VERSION "created by canmatrix"

NS_ :

BS_:

BU_: User ADM_PC_LL25 ADM_PC_BC25 ADM_PC_BP25 ADM_PC_BI25

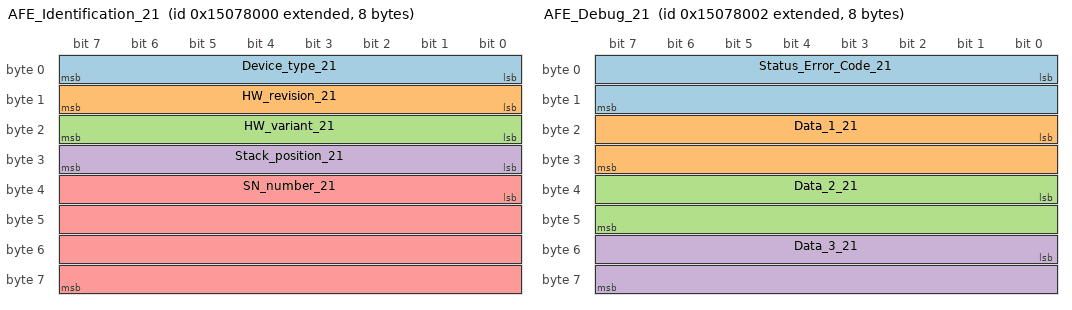
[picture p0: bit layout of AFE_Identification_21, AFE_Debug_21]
BO_ 2500296704 AFE_Identification_21: 8 ADM_PC_BP25
 SG_ Device_type_21 : 0|8@1+ (1,0) [0|255] "" Vector__XXX
 SG_ HW_revision_21 : 8|8@1+ (1,0) [0|255] "" Vector__XXX
 SG_ HW_variant_21 : 16|8@1+ (1,0) [0|255] "" Vector__XXX
 SG_ Stack_position_21 : 24|8@1+ (1,0) [0|255] "" Vector__XXX
 SG_ SN_number_21 : 32|32@1+ (1,0) [0|4294967295] "" Vector__XXX

BO_ 2500296705 AFE_FwInfo_21: 8 ADM_PC_BP25
 SG_ FW_info_mux_21 M : 56|8@1+ (1,0) [0|255] "" Vector__XXX
 SG_ FW_revision_0_21 m0 : 0|8@1+ (1,0) [0|255] "" Vector__XXX
 SG_ FW_revision_1_21 m0 : 8|8@1+ (1,0) [0|255] "" Vector__XXX
 SG_ FW_revision_2_21 m0 : 16|8@1+ (1,0) [0|255] "" Vector__XXX
 SG_ FW_revision_3_21 m0 : 24|8@1+ (1,0) [0|255] "" Vector__XXX
 SG_ FW_revision_4_21 m0 : 32|8@1+ (1,0) [0|255] "" Vector__XXX
 SG_ FW_revision_5_21 m0 : 40|8@1+ (1,0) [0|255] "" Vector__XXX
 SG_ FW_revision_6_21 m0 : 48|8@1+ (1,0) [0|255] "" Vector__XXX
 SG_ FW_revision_7_21 m1 : 0|8@1+ (1,0) [0|255] "" Vector__XXX
 SG_ FW_revision_8_21 m1 : 8|8@1+ (1,0) [0|255] "" Vector__XXX
 SG_ FW_revision_9_21 m1 : 16|8@1+ (1,0) [0|255] "" Vector__XXX
 SG_ FW_revision_10_21 m1 : 24|8@1+ (1,0) [0|255] "" Vector__XXX
 SG_ FW_revision_11_21 m1 : 32|8@1+ (1,0) [0|255] "" Vector__XXX
 SG_ FW_revision_12_21 m1 : 40|8@1+ (1,0) [0|255] "" Vector__XXX
 SG_ FW_revision_13_21 m1 : 48|8@1+ (1,0) [0|255] "" Vector__XXX
 SG_ FW_datecode_0_21 m2 : 0|8@1+ (1,0) [0|255] "" Vector__XXX
 SG_ FW_datecode_1_21 m2 : 8|8@1+ (1,0) [0|255] "" Vector__XXX
 SG_ FW_datecode_2_21 m2 : 16|8@1+ (1,0) [0|255] "" Vector__XXX
 SG_ FW_datecode_3_21 m2 : 24|8@1+ (1,0) [0|255] "" Vector__XXX
 SG_ FW_datecode_4_21 m2 : 32|8@1+ (1,0) [0|255] "" Vector__XXX
 SG_ FW_datecode_5_21 m2 : 40|8@1+ (1,0) [0|255] "" Vector__XXX
 SG_ FW_datecode_6_21 m2 : 48|8@1+ (1,0) [0|255] "" Vector__XXX
 SG_ FW_datecode_7_21 m3 : 0|8@1+ (1,0) [0|255] "" Vector__XXX
 SG_ FW_datecode_8_21 m3 : 8|8@1+ (1,0) [0|255] "" Vector__XXX
 SG_ FW_datecode_9_21 m3 : 16|8@1+ (1,0) [0|255] "" Vector__XXX
 SG_ FW_datecode_10_21 m3 : 24|8@1+ (1,0) [0|255] "" Vector__XXX
 SG_ FW_datecode_11_21 m3 : 32|8@1+ (1,0) [0|255] "" Vector__XXX
 SG_ FW_datecode_12_21 m3 : 40|8@1+ (1,0) [0|255] "" Vector__XXX
 SG_ FW_datecode_13_21 m3 : 48|8@1+ (1,0) [0|255] "" Vector__XXX

BO_ 2500296717 _AFE_Boot_FwInfo_21: 8 ADM_PC_BP25
 SG_ Boot_FW_info_mux_21 M : 56|8@1+ (1,0) [0|255] "" Vector__XXX
 SG_ FW_revision_0_21 m0 : 0|8@1+ (1,0) [0|255] "" Vector__XXX
 SG_ FW_revision_1_21 m0 : 8|8@1+ (1,0) [0|255] "" Vector__XXX
 SG_ FW_revision_2_21 m0 : 16|8@1+ (1,0) [0|255] "" Vector__XXX
 SG_ FW_revision_3_21 m0 : 24|8@1+ (1,0) [0|255] "" Vector__XXX
 SG_ FW_revision_4_21 m0 : 32|8@1+ (1,0) [0|255] "" Vector__XXX
 SG_ FW_revision_5_21 m0 : 40|8@1+ (1,0) [0|255] "" Vector__XXX
 SG_ FW_revision_6_21 m0 : 48|8@1+ (1,0) [0|255] "" Vector__XXX
 SG_ FW_revision_7_21 m1 : 0|8@1+ (1,0) [0|255] "" Vector__XXX
 SG_ FW_revision_8_21 m1 : 8|8@1+ (1,0) [0|255] "" Vector__XXX
 SG_ FW_revision_9_21 m1 : 16|8@1+ (1,0) [0|255] "" Vector__XXX
 SG_ FW_revision_10_21 m1 : 24|8@1+ (1,0) [0|255] "" Vector__XXX
 SG_ FW_revision_11_21 m1 : 32|8@1+ (1,0) [0|255] "" Vector__XXX
 SG_ FW_revision_12_21 m1 : 40|8@1+ (1,0) [0|255] "" Vector__XXX
 SG_ FW_revision_13_21 m1 : 48|8@1+ (1,0) [0|255] "" Vector__XXX
 SG_ FW_datecode_0_21 m2 : 0|8@1+ (1,0) [0|255] "" Vector__XXX
 SG_ FW_datecode_1_21 m2 : 8|8@1+ (1,0) [0|255] "" Vector__XXX
 SG_ FW_datecode_2_21 m2 : 16|8@1+ (1,0) [0|255] "" Vector__XXX
 SG_ FW_datecode_3_21 m2 : 24|8@1+ (1,0) [0|255] "" Vector__XXX
 SG_ FW_datecode_4_21 m2 : 32|8@1+ (1,0) [0|255] "" Vector__XXX
 SG_ FW_datecode_5_21 m2 : 40|8@1+ (1,0) [0|255] "" Vector__XXX
 SG_ FW_datecode_6_21 m2 : 48|8@1+ (1,0) [0|255] "" Vector__XXX
 SG_ FW_datecode_7_21 m3 : 0|8@1+ (1,0) [0|255] "" Vector__XXX
 SG_ FW_datecode_8_21 m3 : 8|8@1+ (1,0) [0|255] "" Vector__XXX
 SG_ FW_datecode_9_21 m3 : 16|8@1+ (1,0) [0|255] "" Vector__XXX
 SG_ FW_datecode_10_21 m3 : 24|8@1+ (1,0) [0|255] "" Vector__XXX
 SG_ FW_datecode_11_21 m3 : 32|8@1+ (1,0) [0|255] "" Vector__XXX
 SG_ FW_datecode_12_21 m3 : 40|8@1+ (1,0) [0|255] "" Vector__XXX
 SG_ FW_datecode_13_21 m3 : 48|8@1+ (1,0) [0|255] "" Vector__XXX

BO_ 2500296706 AFE_Debug_21: 8 ADM_PC_BP25
 SG_ Status_Error_Code_21 : 0|16@1+ (1,0) [0|65535] "" Vector__XXX
 SG_ Data_1_21 : 16|16@1+ (1,0) [0|65535] "" Vector__XXX
 SG_ Data_2_21 : 32|16@1+ (1,0) [0|65535] "" Vector__XXX
 SG_ Data_3_21 : 48|16@1+ (1,0) [0|65535] "" Vector__XXX

BO_ 2500296711 AFE_Status_21: 8 ADM_PC_BP25
 SG_ Running_21 : 0|1@1+ (1,0) [0|1] "" Vector__XXX
 SG_ PWM_21 : 1|1@1+ (1,0) [0|1] "" Vector__XXX
 SG_ Current_dc_loop_mode_21 : 2|1@1+ (1,0) [0|1] "" Vector__XXX
 SG_ Current_ac_loop_mode_21 : 3|1@1+ (1,0) [0|1] "" Vector__XXX
 SG_ Buck_21 : 5|1@1+ (1,0) [0|1] "" Vector__XXX
 SG_ Boost_21 : 6|1@1+ (1,0) [0|1] "" Vector__XXX
 SG_ Precharge_dc_buck_mode_21 : 7|1@1+ (1,0) [0|1] "" Vector__XXX
 SG_ Precharge_dc_boost_mode_21 : 8|1@1+ (1,0) [0|1] "" Vector__XXX
 SG_ Rectifier_3ph_21 : 9|1@1+ (1,0) [0|1] "" Vector__XXX
 SG_ Stack_mode_21 : 10|1@1+ (1,0) [0|1] "" Vector__XXX
 SG_ Master_21 : 11|1@1+ (1,0) [0|1] "" Vector__XXX
 SG_ Slave_21 : 12|1@1+ (1,0) [0|1] "" Vector__XXX
 SG_ Inverter_1ph_21 : 13|1@1+ (1,0) [0|1] "" Vector__XXX
 SG_ Boost_Neutral_21 : 14|1@1+ (1,0) [0|1] "" Vector__XXX
 SG_ Rectifier_1ph_21 : 15|1@1+ (1,0) [0|1] "" Vector__XXX
 SG_ Inverter_3ph_21 : 16|1@1+ (1,0) [0|1] "" Vector__XXX
 SG_ Ready_21 : 17|1@1+ (1,0) [0|1] "" Vector__XXX
 SG_ Inverter_1ph_Sync_21 : 18|1@1+ (1,0) [0|1] "" Vector__XXX
 SG_ Neutral_21 : 19|1@1+ (1,0) [0|1] "" Vector__XXX
 SG_ Rectifier_1ph_Buck_21 : 20|1@1+ (1,0) [0|1] "" Vector__XXX
 SG_ Inverter_1ph_Boost_21 : 21|1@1+ (1,0) [0|1] "" Vector__XXX
 SG_ Rectifier_distributed_21 : 22|1@1+ (1,0) [0|1] "" Vector__XXX
 SG_ MPPT_buck_21 : 23|1@1+ (1,0) [0|1] "" Vector__XXX
 SG_ MPPT_boost_21 : 24|1@1+ (1,0) [0|1] "" Vector__XXX
 SG_ Buck_2p_float_21 : 25|1@1+ (1,0) [0|1] "" Vector__XXX
 SG_ Inverter_1ph_Distributed_21 : 26|1@1+ (1,0) [0|1] "" Vector__XXX

BO_ 2500296710 AFE_Faults_21: 3 ADM_PC_BP25
 SG_ Protection_trip_internal_21 : 0|1@1+ (1,0) [0|1] "" Vector__XXX
 SG_ Protection_trip_external_21 : 1|1@1+ (1,0) [0|1] "" Vector__XXX
 SG_ Phase_U_overcurrent_21 : 2|1@1+ (1,0) [0|1] "" Vector__XXX
 SG_ Phase_U_overvoltage_21 : 3|1@1+ (1,0) [0|1] "" Vector__XXX
 SG_ Phase_U_undervoltage_21 : 4|1@1+ (1,0) [0|1] "" Vector__XXX
 SG_ Phase_V_overvoltage_21 : 5|1@1+ (1,0) [0|1] "" Vector__XXX
 SG_ Phase_V_undervoltage_21 : 6|1@1+ (1,0) [0|1] "" Vector__XXX
 SG_ Phase_V_overcurrent_21 : 7|1@1+ (1,0) [0|1] "" Vector__XXX
 SG_ Phase_W_overvoltage_21 : 8|1@1+ (1,0) [0|1] "" Vector__XXX
 SG_ Phase_W_undervoltage_21 : 9|1@1+ (1,0) [0|1] "" Vector__XXX
 SG_ Phase_W_overcurrent_21 : 10|1@1+ (1,0) [0|1] "" Vector__XXX
 SG_ DC_undervoltage_21 : 11|1@1+ (1,0) [0|1] "" Vector__XXX
 SG_ DC_overvoltage_21 : 12|1@1+ (1,0) [0|1] "" Vector__XXX
 SG_ MOSFET_overtemperature_21 : 13|1@1+ (1,0) [0|1] "" Vector__XXX
 SG_ Inductor_overtemperature_21 : 14|1@1+ (1,0) [0|1] "" Vector__XXX
 SG_ Keep_Alive_not_served_21 : 15|1@1+ (1,0) [0|1] "" Vector__XXX
 SG_ PLL_not_locked_21 : 16|1@1+ (1,0) [0|1] "" Vector__XXX
 SG_ NFO_21 : 20|1@1+ (1,0) [0|1] "" Vector__XXX
 SG_ Measurement_system_failure_21 : 21|1@1+ (1,0) [0|1] "" Vector__XXX
 SG_ EEPROM_failure_21 : 22|1@1+ (1,0) [0|1] "" Vector__XXX
 SG_ System_21 : 23|1@1+ (1,0) [0|1] "" Vector__XXX

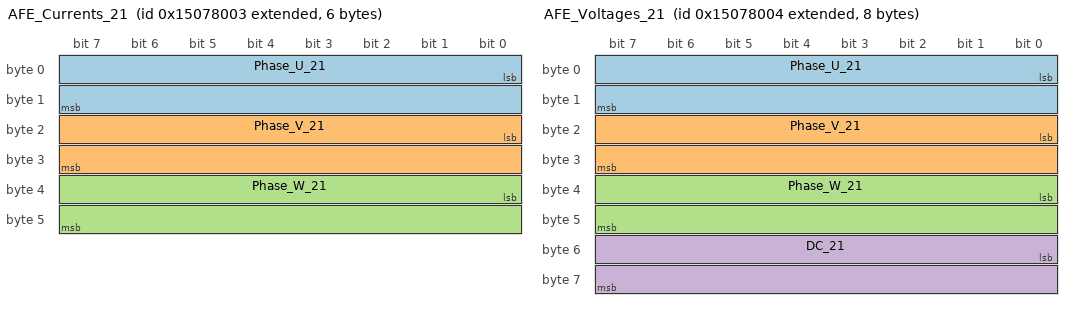
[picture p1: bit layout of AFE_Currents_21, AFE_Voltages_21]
BO_ 2500296707 AFE_Currents_21: 6 ADM_PC_BP25
 SG_ Phase_U_21 : 0|16@1- (0.01,0) [-327.68|327.67] "A" Vector__XXX
 SG_ Phase_V_21 : 16|16@1- (0.01,0) [-327.68|327.67] "A" Vector__XXX
 SG_ Phase_W_21 : 32|16@1- (0.01,0) [-327.68|327.67] "A" Vector__XXX

BO_ 2500296720 AFE_DC_Bus_current_21: 2 ADM_PC_BP25
 SG_ Bus_current_21 : 0|16@1- (0.01,0) [-327.68|327.67] "A" Vector__XXX

BO_ 2500296718 _AFE_Broadcast_21: 8 ADM_PC_BP25
 SG_ Diagnostics_Index_21 M : 56|8@1+ (1,0) [0|255] "" Vector__XXX
 SG_ Phase_U_21 m1 : 8|16@1- (0.01,0) [-327.68|327.67] "A" ADM_PC_BP25
 SG_ Phase_V_21 m1 : 24|16@1- (0.01,0) [-327.68|327.67] "A" ADM_PC_BP25
 SG_ Phase_W_21 m1 : 40|16@1- (0.01,0) [-327.68|327.67] "A" ADM_PC_BP25
 SG_ Stack_position_21 : 0|5@1+ (1,0) [0|31] "" ADM_PC_BP25
 SG_ Group_ID_21 : 5|3@1+ (1,0) [0|7] "" ADM_PC_BP25

BO_ 2500296708 AFE_Voltages_21: 8 ADM_PC_BP25
 SG_ Phase_U_21 : 0|16@1- (0.1,0) [-3276.8|3276.7] "V" Vector__XXX
 SG_ Phase_V_21 : 16|16@1- (0.1,0) [-3276.8|3276.7] "V" Vector__XXX
 SG_ Phase_W_21 : 32|16@1- (0.1,0) [-3276.8|3276.7] "V" Vector__XXX
 SG_ DC_21 : 48|16@1- (0.1,0) [-3276.8|3276.7] "V" Vector__XXX

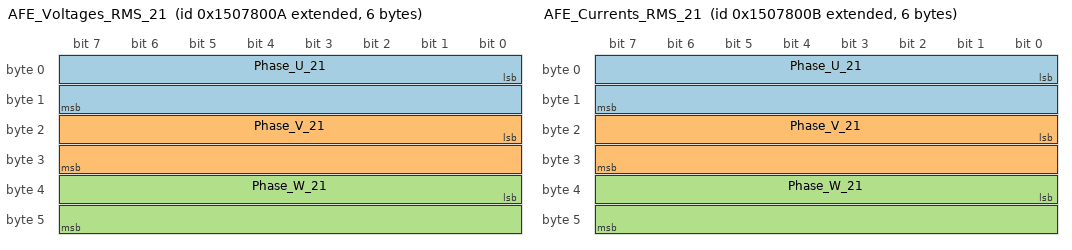
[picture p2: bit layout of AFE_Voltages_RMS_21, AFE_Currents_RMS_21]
BO_ 2500296714 AFE_Voltages_RMS_21: 6 ADM_PC_BP25
 SG_ Phase_U_21 : 0|16@1+ (0.1,0) [0|6553.5] "V" Vector__XXX
 SG_ Phase_V_21 : 16|16@1+ (0.1,0) [0|6553.5] "V" Vector__XXX
 SG_ Phase_W_21 : 32|16@1+ (0.1,0) [0|6553.5] "V" Vector__XXX

BO_ 2500296715 AFE_Currents_RMS_21: 6 ADM_PC_BP25
 SG_ Phase_U_21 : 0|16@1+ (0.01,0) [0.00|655.35] "A" Vector__XXX
 SG_ Phase_V_21 : 16|16@1+ (0.01,0) [0.00|655.35] "A" Vector__XXX
 SG_ Phase_W_21 : 32|16@1+ (0.01,0) [0.00|655.35] "A" Vector__XXX

BO_ 2500296716 AFE_Mains_21: 4 ADM_PC_BP25
 SG_ Frequency_21 : 0|16@1+ (0.01,0) [0.00|655.35] "Hz" Vector__XXX
 SG_ Phase_21 : 16|16@1- (0.1,0) [-3276.8|3276.7] "Deg." Vector__XXX

BO_ 2500296709 AFE_Temperatures_21: 4 ADM_PC_BP25
 SG_ Temp_Bridge_21 : 0|16@1- (0.01,0) [-327.68|327.67] "°C" Vector__XXX
 SG_ Temp_Inductors_21 : 16|16@1- (0.01,0) [-327.68|327.67] "°C" Vector__XXX

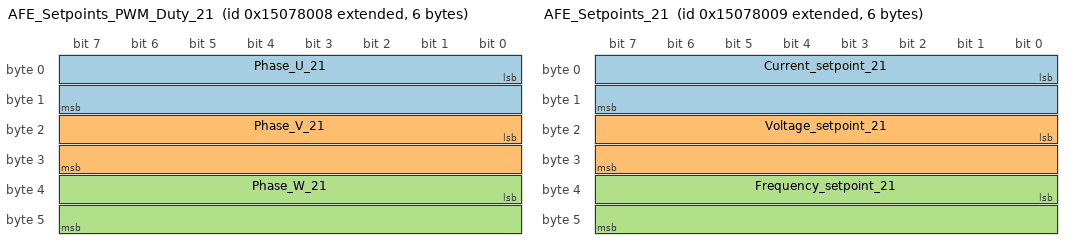
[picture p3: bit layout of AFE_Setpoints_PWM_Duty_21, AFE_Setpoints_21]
BO_ 2500296712 AFE_Setpoints_PWM_Duty_21: 6 ADM_PC_BP25
 SG_ Phase_U_21 : 0|16@1+ (0.001525902,0) [0E-009|99.999987570] "%" Vector__XXX
 SG_ Phase_V_21 : 16|16@1+ (0.001525902,0) [0E-009|99.999987570] "%" Vector__XXX
 SG_ Phase_W_21 : 32|16@1+ (0.001525902,0) [0E-009|99.999987570] "%" Vector__XXX

BO_ 2500296713 AFE_Setpoints_21: 6 ADM_PC_BP25
 SG_ Current_setpoint_21 : 0|16@1- (0.01,0) [-327.68|327.67] "A" Vector__XXX
 SG_ Voltage_setpoint_21 : 16|16@1+ (0.1,0) [0|6553.5] "V" Vector__XXX
 SG_ Frequency_setpoint_21 : 32|16@1+ (0.01,0) [0.00|655.35] "Hz" Vector__XXX

BO_ 2500264032 AFE_Keep_Alive_21: 1 User
 SG_ Keep_Alive_Enable_21 : 0|1@1+ (1,0) [0|1] "" ADM_PC_BP25

BO_ 2500264000 AFE_Mode_Control_21: 8 User
 SG_ Converter_ON_21 : 0|1@1+ (1,0) [0|1] "" ADM_PC_BP25
 SG_ PWM_ON_21 : 1|1@1+ (1,0) [0|1] "" ADM_PC_BP25
 SG_ DC_Current_feedback_ON_21 : 2|1@1+ (1,0) [0|1] "" ADM_PC_BP25
 SG_ AC_Current_feedback_ON_21 : 3|1@1+ (1,0) [0|1] "" ADM_PC_BP25
 SG_ Buck_ON_21 : 5|1@1+ (1,0) [0|1] "" ADM_PC_BP25
 SG_ Boost_ON_21 : 6|1@1+ (1,0) [0|1] "" ADM_PC_BP25
 SG_ Rectifier_3ph_ON_21 : 9|1@1+ (1,0) [0|1] "" ADM_PC_BP25
 SG_ Inverter_1ph_ON_21 : 10|1@1+ (1,0) [0|1] "" ADM_PC_BP25
 SG_ Rectifier_1ph_ON_21 : 11|1@1+ (1,0) [0|1] "" ADM_PC_BP25
 SG_ Boost_Neutral_ON_21 : 12|1@1+ (1,0) [0|1] "" ADM_PC_BP25
 SG_ Inverter_3ph_ON_21 : 13|1@1+ (1,0) [0|1] "" ADM_PC_BP25
 SG_ Inverter_1ph_Sync_ON_21 : 14|1@1+ (1,0) [0|1] "" ADM_PC_BP25
 SG_ Neutral_ON_21 : 15|1@1+ (1,0) [0|1] "" ADM_PC_BP25
 SG_ Rectifier_1ph_Buck_ON_21 : 16|1@1+ (1,0) [0|1] "" ADM_PC_BP25
 SG_ Inverter_1ph_Boost_ON_21 : 17|1@1+ (1,0) [0|1] "" ADM_PC_BP25
 SG_ Rectifier_Distributed_ON_21 : 18|1@1+ (1,0) [0|1] "" ADM_PC_BP25
 SG_ MPPT_buck_ON_21 : 19|1@1+ (1,0) [0|1] "" ADM_PC_BP25
 SG_ MPPT_boost_ON_21 : 20|1@1+ (1,0) [0|1] "" ADM_PC_BP25
 SG_ Buck_2p_float_ON_21 : 21|1@1+ (1,0) [0|1] "" ADM_PC_BP25
 SG_ Inverter_1ph_Distributed_ON_21 : 22|1@1+ (1,0) [0|1] "" ADM_PC_BP25

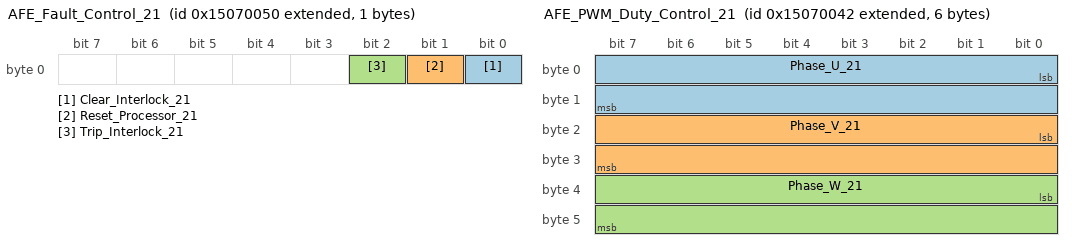
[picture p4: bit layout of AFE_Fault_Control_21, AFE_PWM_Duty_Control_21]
BO_ 2500264016 AFE_Fault_Control_21: 1 User
 SG_ Clear_Interlock_21 : 0|1@1+ (1,0) [0|1] "" ADM_PC_BP25
 SG_ Reset_Processor_21 : 1|1@1+ (1,0) [0|1] "" ADM_PC_BP25
 SG_ Trip_Interlock_21 : 2|1@1+ (1,0) [0|1] "" ADM_PC_BP25

BO_ 2500264001 AFE_Reactive_Current_Setpoint_Co: 2 User
 SG_ Reactive_current_setpoint_21 : 0|16@1- (0.01,0) [-150|150] "A" ADM_PC_BP25

BO_ 2500264002 AFE_PWM_Duty_Control_21: 6 User
 SG_ Phase_U_21 : 0|16@1+ (0.001525902,0) [0E-009|99.999987570] "%" ADM_PC_BP25
 SG_ Phase_V_21 : 16|16@1+ (0.001525902,0) [0E-009|99.999987570] "%" ADM_PC_BP25
 SG_ Phase_W_21 : 32|16@1+ (0.001525902,0) [0E-009|99.999987570] "%" ADM_PC_BP25

BO_ 2500264003 AFE_Current_Setpoint_Control_21: 2 User
 SG_ Current_setpoint_21 : 0|16@1- (0.01,0) [-150|150] "A" ADM_PC_BP25

BO_ 2500264004 AFE_Voltage_Setpoint_Control_21: 2 User
 SG_ Voltage_setpoint_21 : 0|16@1+ (0.1,0) [0|1500] "V" ADM_PC_BP25

BO_ 2500264008 AFE_Frequency_Setpoint_Control_2: 2 User
 SG_ Frequency_setpoint_21 : 0|16@1+ (0.01,0) [40|70] "Hz" ADM_PC_BP25

BO_ 2500264009 AFE_Phase_Setpoint_Control_21: 2 User
 SG_ Phase_setpoint_21 : 0|16@1+ (1,0) [0|360] "deg" ADM_PC_BP25

BO_ 2500264048 AFE_Rectifier_Setpoint_Control_2: 8 User
 SG_ Voltage_setpoint_2_21 : 0|16@1+ (0.1,0) [0|1500] "V" ADM_PC_BP25
 SG_ Current_setpoint_2_21 : 16|16@1- (0.01,0) [-150|150] "A" ADM_PC_BP25

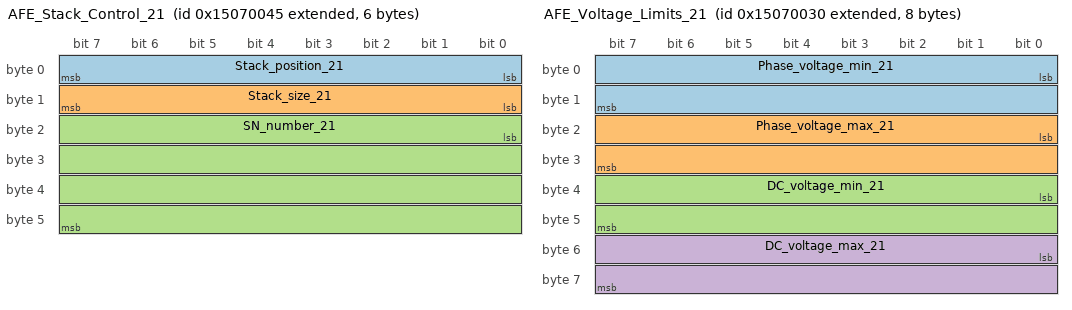
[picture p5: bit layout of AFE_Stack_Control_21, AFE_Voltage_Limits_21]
BO_ 2500264005 AFE_Stack_Control_21: 6 User
 SG_ Stack_position_21 : 0|8@1+ (1,0) [0|255] "" ADM_PC_BP25
 SG_ Stack_size_21 : 8|8@1+ (1,0) [0|255] "" ADM_PC_BP25
 SG_ SN_number_21 : 16|32@1+ (1,0) [0|4294967295] "" ADM_PC_BP25

BO_ 2500263984 AFE_Voltage_Limits_21: 8 User
 SG_ Phase_voltage_min_21 : 0|16@1- (0.1,0) [0|3276.7] "V" ADM_PC_BP25
 SG_ Phase_voltage_max_21 : 16|16@1- (0.1,0) [-3276.8|850] "V" ADM_PC_BP25
 SG_ DC_voltage_min_21 : 32|16@1- (0.1,0) [0|3276.7] "V" ADM_PC_BP25
 SG_ DC_voltage_max_21 : 48|16@1- (0.1,0) [-3276.8|850] "V" ADM_PC_BP25

BO_ 2500263985 AFE_Current_Limits_21: 4 User
 SG_ Phase_current_min_21 : 0|16@1- (0.01,0) [-60|60] "A" ADM_PC_BP25
 SG_ Phase_current_max_21 : 16|16@1- (0.01,0) [-60|60] "A" ADM_PC_BP25

BO_ 2500264012 AFE_Group_Control_21: 1 User
 SG_ Group_ID_21 : 0|8@1+ (1,0) [0|255] "" ADM_PC_BP25

BO_ 2500296719 AFE_Group_Info_21: 1 ADM_PC_BP25
 SG_ Group_ID_21 : 0|8@1+ (1,0) [0|255] "" Vector__XXX

BO_ 2500264033 AFE_System_Flags_Control_21: 8 User
 SG_ Factory_mode_21 : 0|1@1+ (1,0) [0|1] "" ADM_PC_BP25
 SG_ Silent_CAN_mode_21 : 1|1@1+ (1,0) [0|1] "" ADM_PC_BP25

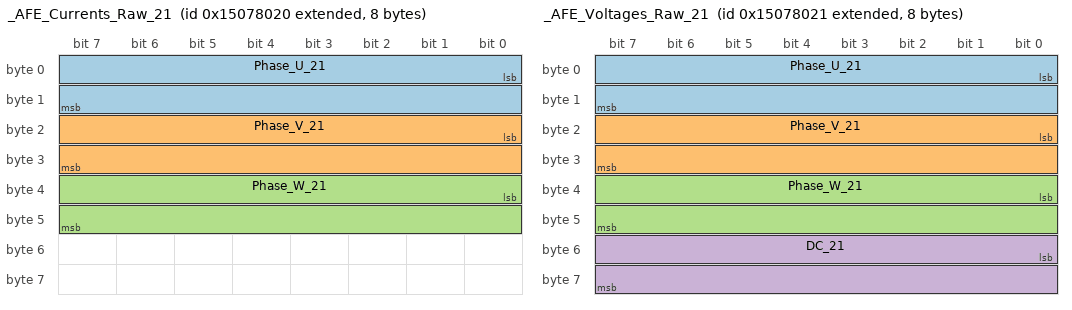
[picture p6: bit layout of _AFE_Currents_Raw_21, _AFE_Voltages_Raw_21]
BO_ 2500296736 _AFE_Currents_Raw_21: 8 ADM_PC_BP25
 SG_ Phase_U_21 : 0|16@1- (1,0) [-32768|32767] "" Vector__XXX
 SG_ Phase_V_21 : 16|16@1- (1,0) [-32768|32767] "" Vector__XXX
 SG_ Phase_W_21 : 32|16@1- (1,0) [-32768|32767] "" Vector__XXX

BO_ 2500296737 _AFE_Voltages_Raw_21: 8 ADM_PC_BP25
 SG_ Phase_U_21 : 0|16@1- (1,0) [-32768|32767] "" Vector__XXX
 SG_ Phase_V_21 : 16|16@1- (1,0) [-32768|32767] "" Vector__XXX
 SG_ Phase_W_21 : 32|16@1- (1,0) [-32768|32767] "" Vector__XXX
 SG_ DC_21 : 48|16@1- (1,0) [-32768|32767] "" Vector__XXX

BO_ 2500264010 _AFE_ADC_Calibration_Mode_21: 1 User
 SG_ Calibration_Index_21 M : 2|5@1+ (1,0) [0|31] "" Vector__XXX
 SG_ Current_U_21 m1 : 0|2@1+ (1,0) [0|3] "" ADM_PC_BP25
 SG_ Current_V_21 m2 : 0|2@1+ (1,0) [0|3] "" ADM_PC_BP25
 SG_ Current_W_21 m3 : 0|2@1+ (1,0) [0|3] "" ADM_PC_BP25
 SG_ Voltage_U_21 m4 : 0|2@1+ (1,0) [0|3] "" ADM_PC_BP25
 SG_ Voltage_V_21 m5 : 0|2@1+ (1,0) [0|3] "" ADM_PC_BP25
 SG_ Voltage_W_21 m6 : 0|2@1+ (1,0) [0|3] "" ADM_PC_BP25
 SG_ Voltage_DC_21 m7 : 0|2@1+ (1,0) [0|3] "" ADM_PC_BP25
 SG_ start_21 : 7|1@1+ (1,0) [0|1] "" ADM_PC_BP25

BO_ 2500264011 _AFE_ADC_Calibration_Setpoint_21: 3 User
 SG_ Calibration_Index_21 M : 16|5@1+ (1,0) [0|31] "" Vector__XXX
 SG_ Current_U_21 m1 : 0|16@1- (0.01,0) [-100|100] "A" ADM_PC_BP25
 SG_ Current_V_21 m2 : 0|16@1- (0.01,0) [-100|100] "A" ADM_PC_BP25
 SG_ Current_W_21 m3 : 0|16@1- (0.01,0) [-100|100] "A" ADM_PC_BP25
 SG_ Voltage_U_21 m4 : 0|16@1+ (0.1,0) [0|1500] "V" ADM_PC_BP25
 SG_ Voltage_V_21 m5 : 0|16@1+ (0.1,0) [0|1500] "V" ADM_PC_BP25
 SG_ Voltage_W_21 m6 : 0|16@1+ (0.1,0) [0|1500] "V" ADM_PC_BP25
 SG_ Voltage_DC_21 m7 : 0|16@1+ (0.1,0) [0|1500] "V" ADM_PC_BP25
 SG_ point_21 : 21|3@1+ (1,0) [0|7] "" ADM_PC_BP25

BO_ 2500264006 _AFE_Calibration_Offset_Update_2: 6 User
 SG_ Calibration_Index_21 M : 16|16@1+ (1,0) [0|65535] "" Vector__XXX
 SG_ Current_U_21 m0 : 0|16@1- (1,0) [-32768|32767] "ADC Counts" ADM_PC_BP25
 SG_ Current_V_21 m1 : 0|16@1- (1,0) [-32768|32767] "ADC Counts" ADM_PC_BP25
 SG_ Current_W_21 m2 : 0|16@1- (1,0) [-32768|32767] "ADC Counts" ADM_PC_BP25
 SG_ Voltage_U_21 m3 : 0|16@1- (1,0) [-32768|32767] "ADC Counts" ADM_PC_BP25
 SG_ Voltage_V_21 m4 : 0|16@1- (1,0) [-32768|32767] "ADC Counts" ADM_PC_BP25
 SG_ Voltage_W_21 m5 : 0|16@1- (1,0) [-32768|32767] "ADC Counts" ADM_PC_BP25
 SG_ Voltage_DC_21 m6 : 0|16@1- (1,0) [-32768|32767] "ADC Counts" ADM_PC_BP25
 SG_ CRC_21 : 32|16@1+ (1,0) [0|65535] "-" ADM_PC_BP25

BO_ 2500264007 _AFE_Calibration_Scale_Update_21: 6 User
 SG_ Calibration_Index_21 M : 16|16@1+ (1,0) [0|65535] "" Vector__XXX
 SG_ Current_U_21 m0 : 0|16@1- (0.0000152587890625,0) [-0.5000000000000000|0.4999847412109375] "scale = 1.0 + value" ADM_PC_BP25
 SG_ Current_V_21 m1 : 0|16@1- (0.0000152587890625,0) [-0.5000000000000000|0.4999847412109375] "scale = 1.0 + value" ADM_PC_BP25
 SG_ Current_W_21 m2 : 0|16@1- (0.0000152587890625,0) [-0.5000000000000000|0.4999847412109375] "scale = 1.0 + value" ADM_PC_BP25
 SG_ Voltage_U_21 m3 : 0|16@1- (0.0000152587890625,0) [-0.5000000000000000|0.4999847412109375] "scale = 1.0 + value" ADM_PC_BP25
 SG_ Voltage_V_21 m4 : 0|16@1- (0.0000152587890625,0) [-0.5000000000000000|0.4999847412109375] "scale = 1.0 + value" ADM_PC_BP25
 SG_ Voltage_W_21 m5 : 0|16@1- (0.0000152587890625,0) [-0.5000000000000000|0.4999847412109375] "scale = 1.0 + value" ADM_PC_BP25
 SG_ Voltage_DC_21 m6 : 0|16@1- (0.0000152587890625,0) [-0.5000000000000000|0.4999847412109375] "scale = 1.0 + value" ADM_PC_BP25
 SG_ CRC_21 : 32|16@1+ (1,0) [0|65535] "-" ADM_PC_BP25

BO_ 2500296785 _AFE_Calibration_Adc_Scale_21: 6 ADM_PC_BP25
 SG_ Adc_Index_21 M : 32|16@1+ (1,0) [0|65535] "" Vector__XXX
 SG_ Current_U_21 m0 : 0|32@1+ (1,0) [0|4294967295] "1 / adc_bins" User
 SG_ Current_V_21 m1 : 0|32@1+ (1,0) [0|4294967295] "1 / adc_bins" User
 SG_ Current_W_21 m2 : 0|32@1+ (1,0) [0|4294967295] "1 / adc_bins" User
 SG_ Voltage_U_21 m3 : 0|32@1+ (1,0) [0|4294967295] "1 / adc_bins" User
 SG_ Voltage_V_21 m4 : 0|32@1+ (1,0) [0|4294967295] "1 / adc_bins" User
 SG_ Voltage_W_21 m5 : 0|32@1+ (1,0) [0|4294967295] "1 / adc_bins" User
 SG_ Voltage_DC_21 m6 : 0|32@1+ (1,0) [0|4294967295] "1 / adc_bins" User

BO_ 2500296786 _AFE_Calibration_Adc_Fs_21: 6 ADM_PC_BP25
 SG_ Adc_Index_21 M : 32|16@1+ (1,0) [0|65535] "" Vector__XXX
 SG_ Current_U_21 m0 : 0|32@1+ (1,0) [0|4294967295] "Fullscale" User
 SG_ Current_V_21 m1 : 0|32@1+ (1,0) [0|4294967295] "Fullscale" User
 SG_ Current_W_21 m2 : 0|32@1+ (1,0) [0|4294967295] "Fullscale" User
 SG_ Voltage_U_21 m3 : 0|32@1+ (1,0) [0|4294967295] "Fullscale" User
 SG_ Voltage_V_21 m4 : 0|32@1+ (1,0) [0|4294967295] "Fullscale" User
 SG_ Voltage_W_21 m5 : 0|32@1+ (1,0) [0|4294967295] "Fullscale" User
 SG_ Voltage_DC_21 m6 : 0|32@1+ (1,0) [0|4294967295] "Fullscale" User

BO_ 2500296787 _AFE_Calibration_Adc_Offset_21: 4 ADM_PC_BP25
 SG_ Adc_Index_21 M : 16|16@1+ (1,0) [0|65535] "" Vector__XXX
 SG_ Current_U_21 m0 : 0|16@1- (1,0) [-32768|32767] "-" User
 SG_ Current_V_21 m1 : 0|16@1- (1,0) [-32768|32767] "-" User
 SG_ Current_W_21 m2 : 0|16@1- (1,0) [-32768|32767] "-" User
 SG_ Voltage_U_21 m3 : 0|16@1- (1,0) [-32768|32767] "-" User
 SG_ Voltage_V_21 m4 : 0|16@1- (1,0) [-32768|32767] "-" User
 SG_ Voltage_W_21 m5 : 0|16@1- (1,0) [-32768|32767] "-" User
 SG_ Voltage_DC_21 m6 : 0|16@1- (1,0) [-32768|32767] "-" User

BO_ 2500296788 _AFE_Calibration_Adc_Gain_21: 4 ADM_PC_BP25
 SG_ Adc_Index_21 M : 16|16@1+ (1,0) [0|65535] "" Vector__XXX
 SG_ Current_U_21 m0 : 0|16@1- (1,0) [-32768|32767] "-" User
 SG_ Current_V_21 m1 : 0|16@1- (1,0) [-32768|32767] "-" User
 SG_ Current_W_21 m2 : 0|16@1- (1,0) [-32768|32767] "-" User
 SG_ Voltage_U_21 m3 : 0|16@1- (1,0) [-32768|32767] "-" User
 SG_ Voltage_V_21 m4 : 0|16@1- (1,0) [-32768|32767] "-" User
 SG_ Voltage_W_21 m5 : 0|16@1- (1,0) [-32768|32767] "-" User
 SG_ Voltage_DC_21 m6 : 0|16@1- (1,0) [-32768|32767] "-" User

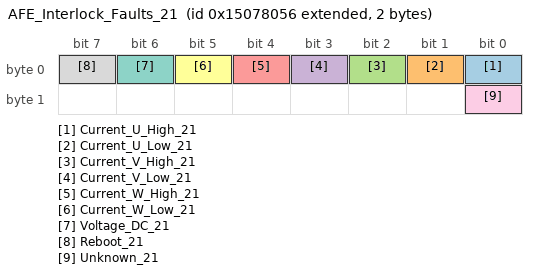
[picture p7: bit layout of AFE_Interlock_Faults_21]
BO_ 2500296790 AFE_Interlock_Faults_21: 2 ADM_PC_BP25
 SG_ Current_U_High_21 : 0|1@1+ (1,0) [0|1] "" Vector__XXX
 SG_ Current_U_Low_21 : 1|1@1+ (1,0) [0|1] "" Vector__XXX
 SG_ Current_V_High_21 : 2|1@1+ (1,0) [0|1] "" Vector__XXX
 SG_ Current_V_Low_21 : 3|1@1+ (1,0) [0|1] "" Vector__XXX
 SG_ Current_W_High_21 : 4|1@1+ (1,0) [0|1] "" Vector__XXX
 SG_ Current_W_Low_21 : 5|1@1+ (1,0) [0|1] "" Vector__XXX
 SG_ Voltage_DC_21 : 6|1@1+ (1,0) [0|1] "" Vector__XXX
 SG_ Reboot_21 : 7|1@1+ (1,0) [0|1] "" Vector__XXX
 SG_ Unknown_21 : 8|1@1+ (1,0) [0|1] "" Vector__XXX

BO_TX_BU_ 2500264000 : User,ADM_PC_LL25,ADM_PC_BC25,ADM_PC_BI25;
BO_TX_BU_ 2500264003 : User,ADM_PC_LL25,ADM_PC_BC25,ADM_PC_BI25;
BO_TX_BU_ 2500264004 : User,ADM_PC_LL25,ADM_PC_BC25,ADM_PC_BI25;
CM_ BO_ 2500296704  "Identification of the device";
CM_ BO_ 2500296705  "Git revision of the DSP firmware";
CM_ BO_ 2500296717  "Git revision of the bootloader firmware.";
CM_ BO_ 2500296706  "Values for debugging of HW/SW problems";
CM_ BO_ 2500296711  "Status bitfield";
CM_ BO_ 2500296710  "Fault bitfield";
CM_ BO_ 2500296707  "Current of phases U, V, W";
CM_ BO_ 2500296720  "Current of of the DC Bus";
CM_ BO_ 2500296718  "All AFEs will listen to this message";
CM_ BO_ 2500296715  "RMS Current of phases U, V, W";
CM_ BO_ 2500296716  "Three-Phase mains health (frequency, phase...)";
CM_ BO_ 2500296709  "Readouts of the module temperature sensors";
CM_ BO_ 2500296712  "Setpoints";
CM_ BO_ 2500296713  "Setpoints";
CM_ BO_ 2500264032  "Keep alive ping message. ";
CM_ BO_ 2500264000  "Operation Mode control: sets the converter operation mode";
CM_ BO_ 2500264016  "Fault Control: actions to clear faults and reset the system";
CM_ BO_ 2500264001  "Reactive power setpoint control.";
CM_ BO_ 2500264002  "PWM duty cycle control";
CM_ BO_ 2500264003  "Current setpoint control";
CM_ BO_ 2500264004  "Voltage setpoint control";
CM_ BO_ 2500264008  "Frequency setpoint control";
CM_ BO_ 2500264009  "Phase setpoint control";
CM_ BO_ 2500264048  "Additional voltage and current setpoints in single-phase rectifier and inverter control modes.";
CM_ BO_ 2500264005  "PFC stack control";
CM_ BO_ 2500263984  "Set the input and output voltage limits (minimum and maximum)";
CM_ BO_ 2500263985  "Set the output current limits (mminimum and maximum)";
CM_ BO_ 2500264012  "Set the Group ID of the device";
CM_ BO_ 2500296719  "Contains the Group ID of the device";
CM_ BO_ 2500264033  "Control the system flags";
CM_ BO_ 2500296736  "Current of phases A and B";
CM_ BO_ 2500296737  "Current of phases A and B";
CM_ BO_ 2500264010  "Automatic ADC calibration.";
CM_ BO_ 2500264011  "Setpoint for automatic ADC calibration.";
CM_ BO_ 2500264006  "Update of the calibration table for offsets.";
CM_ BO_ 2500264007  "Update of the calibration table for scales.";
CM_ BO_ 2500296785  "
                Adc scale (resolution) value of readouts.
            ";
CM_ BO_ 2500296786  "
                Adc fullscale value of readouts.
            ";
CM_ BO_ 2500296787  "
                Readout of ADC calibration data (offset) from EEPROM.
            ";
CM_ BO_ 2500296788  "
                Readout of ADC calibration data (gain) from EEPROM.
            ";
CM_ BO_ 2500296790  "Fault bitfield";

CM_ SG_ 2500296704 Device_type_21 "The device identification field, uniquely identifies the sender in the network";
CM_ SG_ 2500296704 HW_revision_21 "The hardware revision number";
CM_ SG_ 2500296704 HW_variant_21 "The DSP firmware revision number";
CM_ SG_ 2500296704 Stack_position_21 "Position of the module within the stack";
CM_ SG_ 2500296704 SN_number_21 "Unique module serial number";
CM_ SG_ 2500296705 FW_revision_0_21 "Character 0";
CM_ SG_ 2500296705 FW_revision_1_21 "Character 1";
CM_ SG_ 2500296705 FW_revision_2_21 "Character 2";
CM_ SG_ 2500296705 FW_revision_3_21 "Character 3";
CM_ SG_ 2500296705 FW_revision_4_21 "Character 3";
CM_ SG_ 2500296705 FW_revision_5_21 "Character 3";
CM_ SG_ 2500296705 FW_revision_6_21 "Character 3";
CM_ SG_ 2500296705 FW_revision_7_21 "Character 7";
CM_ SG_ 2500296705 FW_revision_8_21 "Character 8";
CM_ SG_ 2500296705 FW_revision_9_21 "Character 9";
CM_ SG_ 2500296705 FW_revision_10_21 "Character 10";
CM_ SG_ 2500296705 FW_revision_11_21 "Character 11";
CM_ SG_ 2500296705 FW_revision_12_21 "Character 12";
CM_ SG_ 2500296705 FW_revision_13_21 "Character 13";
CM_ SG_ 2500296705 FW_datecode_0_21 "Character 0";
CM_ SG_ 2500296705 FW_datecode_1_21 "Character 1";
CM_ SG_ 2500296705 FW_datecode_2_21 "Character 2";
CM_ SG_ 2500296705 FW_datecode_3_21 "Character 3";
CM_ SG_ 2500296705 FW_datecode_4_21 "Character 3";
CM_ SG_ 2500296705 FW_datecode_5_21 "Character 3";
CM_ SG_ 2500296705 FW_datecode_6_21 "Character 3";
CM_ SG_ 2500296705 FW_datecode_7_21 "Character 7";
CM_ SG_ 2500296705 FW_datecode_8_21 "Character 8";
CM_ SG_ 2500296705 FW_datecode_9_21 "Character 9";
CM_ SG_ 2500296705 FW_datecode_10_21 "Character 10";
CM_ SG_ 2500296705 FW_datecode_11_21 "Character 11";
CM_ SG_ 2500296705 FW_datecode_12_21 "Character 12";
CM_ SG_ 2500296705 FW_datecode_13_21 "Character 13";
CM_ SG_ 2500296717 FW_revision_0_21 "Character 0";
CM_ SG_ 2500296717 FW_revision_1_21 "Character 1";
CM_ SG_ 2500296717 FW_revision_2_21 "Character 2";
CM_ SG_ 2500296717 FW_revision_3_21 "Character 3";
CM_ SG_ 2500296717 FW_revision_4_21 "Character 3";
CM_ SG_ 2500296717 FW_revision_5_21 "Character 3";
CM_ SG_ 2500296717 FW_revision_6_21 "Character 3";
CM_ SG_ 2500296717 FW_revision_7_21 "Character 7";
CM_ SG_ 2500296717 FW_revision_8_21 "Character 8";
CM_ SG_ 2500296717 FW_revision_9_21 "Character 9";
CM_ SG_ 2500296717 FW_revision_10_21 "Character 10";
CM_ SG_ 2500296717 FW_revision_11_21 "Character 11";
CM_ SG_ 2500296717 FW_revision_12_21 "Character 12";
CM_ SG_ 2500296717 FW_revision_13_21 "Character 13";
CM_ SG_ 2500296717 FW_datecode_0_21 "Character 0";
CM_ SG_ 2500296717 FW_datecode_1_21 "Character 1";
CM_ SG_ 2500296717 FW_datecode_2_21 "Character 2";
CM_ SG_ 2500296717 FW_datecode_3_21 "Character 3";
CM_ SG_ 2500296717 FW_datecode_4_21 "Character 3";
CM_ SG_ 2500296717 FW_datecode_5_21 "Character 3";
CM_ SG_ 2500296717 FW_datecode_6_21 "Character 3";
CM_ SG_ 2500296717 FW_datecode_7_21 "Character 7";
CM_ SG_ 2500296717 FW_datecode_8_21 "Character 8";
CM_ SG_ 2500296717 FW_datecode_9_21 "Character 9";
CM_ SG_ 2500296717 FW_datecode_10_21 "Character 10";
CM_ SG_ 2500296717 FW_datecode_11_21 "Character 11";
CM_ SG_ 2500296717 FW_datecode_12_21 "Character 12";
CM_ SG_ 2500296717 FW_datecode_13_21 "Character 13";
CM_ SG_ 2500296706 Status_Error_Code_21 "Main status / error code as defined in errno/errno.h";
CM_ SG_ 2500296706 Data_1_21 "Additional information for the error/status";
CM_ SG_ 2500296706 Data_2_21 "Additional information for the error/status";
CM_ SG_ 2500296706 Data_3_21 "Additional information for the error/status";
CM_ SG_ 2500296711 Running_21 "Indicates if converter is running.";
CM_ SG_ 2500296711 PWM_21 "Indicates if converter is in PWM control mode.";
CM_ SG_ 2500296711 Current_dc_loop_mode_21 "Indicates if the current DC loop is enabled.";
CM_ SG_ 2500296711 Current_ac_loop_mode_21 "Indicates if the current AC loop is enabled.";
CM_ SG_ 2500296711 Buck_21 "Indicates if converter is in buck control mode.";
CM_ SG_ 2500296711 Boost_21 "Indicates if converter is in boost control mode.";
CM_ SG_ 2500296711 Precharge_dc_buck_mode_21 "Indicates if the precharge DC mode is enabled - buck direction.";
CM_ SG_ 2500296711 Precharge_dc_boost_mode_21 "Indicates if the precharge DC mode is enabled - boost direction.";
CM_ SG_ 2500296711 Rectifier_3ph_21 "Indicates if converter is in three-phase rectifier control mode.";
CM_ SG_ 2500296711 Stack_mode_21 "Indicates if converter is operating in stack mode.";
CM_ SG_ 2500296711 Master_21 "Indicates if converter is master in the stack.";
CM_ SG_ 2500296711 Slave_21 "Indicates if converter is slave in the stack.";
CM_ SG_ 2500296711 Inverter_1ph_21 "Indicates if converter is in single-phase inverter control mode.";
CM_ SG_ 2500296711 Boost_Neutral_21 "Indicates if converter is in boost control mode with neutral generation.";
CM_ SG_ 2500296711 Rectifier_1ph_21 "Indicates if converter is in single-phase rectifier control mode.";
CM_ SG_ 2500296711 Inverter_3ph_21 "Indicates if converter is in three-phase inverter control mode.";
CM_ SG_ 2500296711 Ready_21 "Indicates if converter is ready for operation.";
CM_ SG_ 2500296711 Inverter_1ph_Sync_21 "Single-phase inverter control mode with phase synchronization.";
CM_ SG_ 2500296711 Neutral_21 "Open-loop neutral generation.";
CM_ SG_ 2500296711 Rectifier_1ph_Buck_21 "Single-phase rectifier with buck on one leg.";
CM_ SG_ 2500296711 Inverter_1ph_Boost_21 "Single-phase inverter with boost on one leg.";
CM_ SG_ 2500296711 Rectifier_distributed_21 "Not available at the moment";
CM_ SG_ 2500296711 MPPT_buck_21 "Not available at the moment";
CM_ SG_ 2500296711 MPPT_boost_21 "Not available at the moment";
CM_ SG_ 2500296711 Buck_2p_float_21 "Buck in phases L1 and L2. Phase L3 is left floating (high impedance)";
CM_ SG_ 2500296711 Inverter_1ph_Distributed_21 "Single-phase inverter mode  distributed";
CM_ SG_ 2500296710 Protection_trip_internal_21 "This flagg is asserted if the interlock is open due to an internal fault condition (self-protection)";
CM_ SG_ 2500296710 Protection_trip_external_21 "This flag is asserted if the interlock is open due to an external condition received in the module.";
CM_ SG_ 2500296710 Phase_U_overcurrent_21 "Indicates an overcurrent event on Phase U. The overcurrent event is triggered when the measured phase current is over the programmed current limit.";
CM_ SG_ 2500296710 Phase_U_overvoltage_21 "Indicates an overvoltage event on Phase U. The overvoltage event is triggered when the measured phase voltage is over the programmed voltage limit.";
CM_ SG_ 2500296710 Phase_U_undervoltage_21 "Indicates an undervoltage event on Phase U. The overvoltage event is triggered when the measured phase voltage is over the programmed voltage limit.";
CM_ SG_ 2500296710 Phase_V_overvoltage_21 "Indicates an overvoltage event on Phase V. The overvoltage event is triggered when the measured phase voltage is over the programmed voltage limit.";
CM_ SG_ 2500296710 Phase_V_undervoltage_21 "Indicates an undervoltage event on Phase U. The overvoltage event is triggered when the measured phase voltage is over the programmed voltage limit.";
CM_ SG_ 2500296710 Phase_V_overcurrent_21 "Indicates an overcurrent event on Phase U. The overcurrent event is triggered when the measured phase current is over the programmed current limit.";
CM_ SG_ 2500296710 Phase_W_overvoltage_21 "Indicates an overvoltage event on Phase U. The overvoltage event is triggered when the measured phase voltage is over the programmed voltage limit.";
CM_ SG_ 2500296710 Phase_W_undervoltage_21 "Indicates an undervoltage event on Phase U. The overvoltage event is triggered when the measured phase voltage is over the programmed voltage limit.";
CM_ SG_ 2500296710 Phase_W_overcurrent_21 "Indicates an overcurrent event on Phase U. The overcurrent event is triggered when the measured phase current is over the programmed current limit.";
CM_ SG_ 2500296710 DC_undervoltage_21 "DC bus undervoltage condition. The undervoltage condition is asserted when the measured dc bus voltage is under the programmed voltage limit.";
CM_ SG_ 2500296710 DC_overvoltage_21 "DC bus overvoltage condition. The overvoltage condition is asserted when the measured dc bus voltage is over the programmed voltage limit.";
CM_ SG_ 2500296710 MOSFET_overtemperature_21 "This flag is asserted when the temperature of the MOSFET block is too high.";
CM_ SG_ 2500296710 Inductor_overtemperature_21 "This flag is asserted when the temperature of the inductor block is too high.";
CM_ SG_ 2500296710 Keep_Alive_not_served_21 "The Keep Alive feature is enabled but it was not served with the periodic message.";
CM_ SG_ 2500296710 PLL_not_locked_21 "Flag asserted when in rectifier modes, the PLL went out of lock condition";
CM_ SG_ 2500296710 Measurement_system_failure_21 "The voltages/currents measurement system is malfunctionning, and readouts are not guaranteed to be accurate.";
CM_ SG_ 2500296710 EEPROM_failure_21 "The configuration EEPROM failed to load or save the module configuration.";
CM_ SG_ 2500296707 Phase_U_21 "Phase current is the MOSFET loop current, in the branch U of the converter.";
CM_ SG_ 2500296707 Phase_V_21 "Phase current is the MOSFET loop current, in the branch V of the converter.";
CM_ SG_ 2500296707 Phase_W_21 "Phase current is the MOSFET loop current, in the branch W of the converter.";
CM_ SG_ 2500296720 Bus_current_21 "DC Bus current is possitive when current goes from input to output";
CM_ SG_ 2500296718 Phase_U_21 "Phase current is the MOSFET loop current, in the branch U of the converter.";
CM_ SG_ 2500296718 Phase_V_21 "Phase current is the MOSFET loop current, in the branch V of the converter.";
CM_ SG_ 2500296718 Phase_W_21 "Phase current is the MOSFET loop current, in the branch W of the converter.";
CM_ SG_ 2500296718 Stack_position_21 "Sender Stack position";
CM_ SG_ 2500296718 Group_ID_21 "Sender Group ID";
CM_ SG_ 2500296715 Phase_U_21 "RMS Phase current is the MOSFET loop current, in the branch U of the converter.";
CM_ SG_ 2500296715 Phase_V_21 "RMS Phase current is the MOSFET loop current, in the branch V of the converter.";
CM_ SG_ 2500296715 Phase_W_21 "RMS Phase current is the MOSFET loop current, in the branch W of the converter.";
CM_ SG_ 2500296716 Frequency_21 "Frequency of Three-Phase system";
CM_ SG_ 2500296716 Phase_21 "Phase of Three-Phase system";
CM_ SG_ 2500296709 Temp_Bridge_21 "Temperature of the MOSFET block";
CM_ SG_ 2500296709 Temp_Inductors_21 "Temperature of the inductors";
CM_ SG_ 2500296712 Phase_U_21 "The actual PWM duty cycle setpoint";
CM_ SG_ 2500296712 Phase_V_21 "The actual PWM duty cycle setpoint";
CM_ SG_ 2500296712 Phase_W_21 "The actual PWM duty cycle setpoint";
CM_ SG_ 2500296713 Current_setpoint_21 "The actual current setpoint";
CM_ SG_ 2500296713 Voltage_setpoint_21 "The actual voltage setpoint";
CM_ SG_ 2500296713 Frequency_setpoint_21 "The actual frequency setpoint";
CM_ SG_ 2500264032 Keep_Alive_Enable_21 "If set to 1, module will expect to receive this message every second repeatedly, or it will stop operation";
CM_ SG_ 2500264000 Converter_ON_21 "Enable the converter.";
CM_ SG_ 2500264000 PWM_ON_21 "Enable the PWM control mode.";
CM_ SG_ 2500264000 DC_Current_feedback_ON_21 "Enable the DC current loop";
CM_ SG_ 2500264000 AC_Current_feedback_ON_21 "Enable the AC current loop";
CM_ SG_ 2500264000 Buck_ON_21 "Enable the buck control mode.";
CM_ SG_ 2500264000 Boost_ON_21 "Enable the boost control mode.";
CM_ SG_ 2500264000 Rectifier_3ph_ON_21 "Enable the three-phase rectifier control mode.";
CM_ SG_ 2500264000 Inverter_1ph_ON_21 "Enable the single-phase inverter control mode.";
CM_ SG_ 2500264000 Rectifier_1ph_ON_21 "Enable the single-phase rectifier control mode.";
CM_ SG_ 2500264000 Boost_Neutral_ON_21 "Enable the boost control mode with neutral generation.";
CM_ SG_ 2500264000 Inverter_3ph_ON_21 "Enable the three-phase inverter control mode.";
CM_ SG_ 2500264000 Inverter_1ph_Sync_ON_21 "Single-phase inverter control mode with phase synchronization.";
CM_ SG_ 2500264000 Neutral_ON_21 "Open-loop neutral generation.";
CM_ SG_ 2500264000 Rectifier_1ph_Buck_ON_21 "Single-phase rectifier with buck on one leg.";
CM_ SG_ 2500264000 Inverter_1ph_Boost_ON_21 "Single-phase inverter with boost on one leg.";
CM_ SG_ 2500264000 Rectifier_Distributed_ON_21 "Single-phase (floating) distributed rectifier";
CM_ SG_ 2500264000 MPPT_buck_ON_21 "MPPT buck";
CM_ SG_ 2500264000 MPPT_boost_ON_21 "MPPT boost";
CM_ SG_ 2500264000 Buck_2p_float_ON_21 "Boost on L1 and L2. Floating L3 (high-impedance)";
CM_ SG_ 2500264000 Inverter_1ph_Distributed_ON_21 "Single-phase inverter mode distributed";
CM_ SG_ 2500264016 Clear_Interlock_21 "Clears the converter interlock";
CM_ SG_ 2500264016 Reset_Processor_21 "Reset the converter DSP";
CM_ SG_ 2500264016 Trip_Interlock_21 "Trip the inetrnal Interlock";
CM_ SG_ 2500264001 Reactive_current_setpoint_21 "This defines reactive current setpoint for 3-phase rectifier mode";
CM_ SG_ 2500264002 Phase_U_21 "The actual PWM duty cycle setpoint";
CM_ SG_ 2500264002 Phase_V_21 "The actual PWM duty cycle setpoint";
CM_ SG_ 2500264002 Phase_W_21 "The actual PWM duty cycle setpoint";
CM_ SG_ 2500264003 Current_setpoint_21 "Sets the output current setpoint. Active only when the current loop is enabled";
CM_ SG_ 2500264004 Voltage_setpoint_21 "Sets the output voltage setpoint. Active only when the voltage loop is enabled";
CM_ SG_ 2500264008 Frequency_setpoint_21 "Sets the frequency for single-phase and three-phase generator modes.";
CM_ SG_ 2500264009 Phase_setpoint_21 "Sets the phase for inverter control modes.";
CM_ SG_ 2500264005 Stack_position_21 "The converter position within the stack";
CM_ SG_ 2500264005 Stack_size_21 "How many PFC converters are in stack in total";
CM_ SG_ 2500264005 SN_number_21 "Unique module serial number";
CM_ SG_ 2500263984 Phase_voltage_min_21 "Minimum tolerated phase voltage";
CM_ SG_ 2500263984 Phase_voltage_max_21 "Maximum allowable phase voltage";
CM_ SG_ 2500263984 DC_voltage_min_21 "Minimum allowable dc voltage";
CM_ SG_ 2500263984 DC_voltage_max_21 "Maximum allowable dc voltage";
CM_ SG_ 2500263985 Phase_current_min_21 "Minimum allowable output current";
CM_ SG_ 2500263985 Phase_current_max_21 "Maximum allowable output current";
CM_ SG_ 2500264012 Group_ID_21 "Desired group ID for the device";
CM_ SG_ 2500296719 Group_ID_21 "Group ID of the device";
CM_ SG_ 2500264033 Factory_mode_21 "Customers MUST NOT USE this bit. If set to 1, module will enter in factory mode. ";
CM_ SG_ 2500264033 Silent_CAN_mode_21 "Customers MUST NOT USE this bit. If set to 1, module will enter in factory mode. ";
CM_ SG_ 2500264010 start_21 "Start automatic calibration. Multiplexer index must be 0!";
CM_ SG_ 2500264011 point_21 "Calibration point index.";
CM_ SG_ 2500264006 CRC_21 "Checksum of bytes 0 to 3, CRC-CCITT, corresponding to qChecksum (www.qt.io)";
CM_ SG_ 2500264007 CRC_21 "Checksum of bytes 0 to 3, CRC-CCITT, corresponding to qChecksum (www.qt.io)";
CM_ SG_ 2500296790 Current_U_High_21 "This flag is set if a hight current on U tripped the internal interlock";
CM_ SG_ 2500296790 Current_U_Low_21 "This flag is set if a low current on U tripped the internal interlock";
CM_ SG_ 2500296790 Current_V_High_21 "This flag is set if a hight current on V tripped the internal interlock";
CM_ SG_ 2500296790 Current_V_Low_21 "This flag is set if a low current on V tripped the internal interlock";
CM_ SG_ 2500296790 Current_W_High_21 "This flag is set if a hight current on W tripped the internal interlock";
CM_ SG_ 2500296790 Current_W_Low_21 "This flag is set if a low current on W tripped the internal interlock";
CM_ SG_ 2500296790 Voltage_DC_21 "This flag is set if a voltage on DC tripped the internal interlock";
CM_ SG_ 2500296790 Reboot_21 "This flag is set if a reboot tripped the internal interlock";
CM_ SG_ 2500296790 Unknown_21 "This flag the reason for the internal interlock is unknown";

BA_DEF_ BO_ "SystemMessageLongSymbol" STRING;

BA_ "SystemMessageLongSymbol" BO_ 2500264001 "AFE_Reactive_Current_Setpoint_Control_21";
BA_ "SystemMessageLongSymbol" BO_ 2500264008 "AFE_Frequency_Setpoint_Control_21";
BA_ "SystemMessageLongSymbol" BO_ 2500264048 "AFE_Rectifier_Setpoint_Control_21";
BA_ "SystemMessageLongSymbol" BO_ 2500264006 "_AFE_Calibration_Offset_Update_21";

VAL_ 2500296704 Device_type_21 7 "AFE";
VAL_ 2500296710 Protection_trip_internal_21 1 "fault";
VAL_ 2500296710 Protection_trip_external_21 1 "fault";
VAL_ 2500296710 Phase_U_overcurrent_21 1 "fault";
VAL_ 2500296710 Phase_U_overvoltage_21 1 "fault";
VAL_ 2500296710 Phase_U_undervoltage_21 1 "fault";
VAL_ 2500296710 Phase_V_overvoltage_21 1 "fault";
VAL_ 2500296710 Phase_V_undervoltage_21 1 "fault";
VAL_ 2500296710 Phase_V_overcurrent_21 1 "fault";
VAL_ 2500296710 Phase_W_overvoltage_21 1 "fault";
VAL_ 2500296710 Phase_W_undervoltage_21 1 "fault";
VAL_ 2500296710 Phase_W_overcurrent_21 1 "fault";
VAL_ 2500296710 DC_undervoltage_21 1 "fault";
VAL_ 2500296710 DC_overvoltage_21 1 "fault";
VAL_ 2500296710 MOSFET_overtemperature_21 1 "fault";
VAL_ 2500296710 Inductor_overtemperature_21 1 "fault";
VAL_ 2500296710 Keep_Alive_not_served_21 1 "fault";
VAL_ 2500296710 PLL_not_locked_21 1 "fault";
VAL_ 2500296710 NFO_21 1 "fault";
VAL_ 2500296710 Measurement_system_failure_21 1 "fault";
VAL_ 2500296710 EEPROM_failure_21 1 "fault";
VAL_ 2500296710 System_21 1 "fault";
VAL_ 2500296790 Current_U_High_21 1 "fault";
VAL_ 2500296790 Current_U_Low_21 1 "fault";
VAL_ 2500296790 Current_V_High_21 1 "fault";
VAL_ 2500296790 Current_V_Low_21 1 "fault";
VAL_ 2500296790 Current_W_High_21 1 "fault";
VAL_ 2500296790 Current_W_Low_21 1 "fault";
VAL_ 2500296790 Voltage_DC_21 1 "fault";
VAL_ 2500296790 Reboot_21 1 "fault";
VAL_ 2500296790 Unknown_21 1 "fault";
SIG_VALTYPE_ 2500296785 Current_U_21 : 1;
SIG_VALTYPE_ 2500296785 Current_V_21 : 1;
SIG_VALTYPE_ 2500296785 Current_W_21 : 1;
SIG_VALTYPE_ 2500296785 Voltage_U_21 : 1;
SIG_VALTYPE_ 2500296785 Voltage_V_21 : 1;
SIG_VALTYPE_ 2500296785 Voltage_W_21 : 1;
SIG_VALTYPE_ 2500296785 Voltage_DC_21 : 1;
SIG_VALTYPE_ 2500296786 Current_U_21 : 1;
SIG_VALTYPE_ 2500296786 Current_V_21 : 1;
SIG_VALTYPE_ 2500296786 Current_W_21 : 1;
SIG_VALTYPE_ 2500296786 Voltage_U_21 : 1;
SIG_VALTYPE_ 2500296786 Voltage_V_21 : 1;
SIG_VALTYPE_ 2500296786 Voltage_W_21 : 1;
SIG_VALTYPE_ 2500296786 Voltage_DC_21 : 1;
